# YC3122 register map
Series: ARMCM0; File version: 1.0
CPU: CM0 r1p0, little endian, no MPU, no FPU, 8 interrupt priority bits
Registers are 32-bit, read-write, reset 0x0 unless marked. A register's access mark holds for its fields unless they carry their own. Offsets are from the block's base; [hi:lo] are bit positions.

## MRSTGEN
Base 0x000F8574
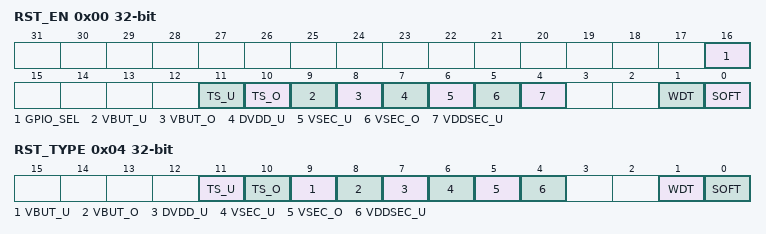
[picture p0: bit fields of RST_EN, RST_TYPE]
0x00 RST_EN
  [16] GPIO_SEL — 复位GPIO选择 0: ice_rst/m0_dbg_rst复位外设时,不 复位GPIO. 1: ice_rst/m0_dbg_rst复位外设时,复 位GPIO
  [11] TS_U — 1: 使能低温自检复位功能
  [10] TS_O — 1: 使能高温自检复位功能
  [9] VBUT_U — 1: 使能纽扣电池3.3v输出低压自检复位功能
  [8] VBUT_O — 1: 使能纽扣电池3.3v输出高压自检复位功能
  [7] DVDD_U — 1: 使能纽扣电池1.2v输出低压自检复位功能
  [6] VSEC_U — 1: 使能锂电池3.3v输出低压自检复位功能
  [5] VSEC_O — 1: 使能锂电池3.3v输出高压自检复位功能
  [4] VDDSEC_U — 1: 使能安全域电源1.2v输出低压自检复位功能
  [1] WDT — 1: 使能看门狗复位功能
  [0] SOFT — 1: 使能软件复位功能
0x04 RST_TYPE
  [11] TS_U — 软件可读写,若对应的复位信号触发,则硬件自动置1 ,清0需由软件完成。
  [10] TS_O — 软件可读写,若对应的复位信号触发,则硬件自动置1 ,清0需由软件完成。
  [9] VBUT_U — 软件可读写,若对应的复位信号触发,则硬件自动置1 ,清0需由软件完成。
  [8] VBUT_O — 软件可读写,若对应的复位信号触发,则硬件自动置1 ,清0需由软件完成。
  [7] DVDD_U — 软件可读写,若对应的复位信号触发,则硬件自动置1 ,清0需由软件完成。
  [6] VSEC_U — 软件可读写,若对应的复位信号触发,则硬件自动置1 ,清0需由软件完成。
  [5] VSEC_O — 软件可读写,若对应的复位信号触发,则硬件自动置1 ,清0需由软件完成。
  [4] VDDSEC_U — 软件可读写,若对应的复位信号触发,则硬件自动置1 ,清0需由软件完成。
  [1] WDT — 软件可读写,若对应的复位信号触发,则硬件自动置1 ,清0需由软件完成。
  [0] SOFT — 软件可读写,若对应的复位信号触发,则硬件自动置1 ,清0需由软件完成。
0x08 RESET
  [7:0] RESET wo — 复位使能: 写入 "0x55" ,触发软件复位,sw_rst 写入 "0x50" ,触发软件复位,ic_rst 写入 "0xAB“ ,触发sci复位,rst_sci 写入 "0xAE“ ,触发sci2复位,rst_sci_ 2 写入 "0xC3" ,触发7811复位,rst_7811

## MSECURE
Base 0x000F85C0
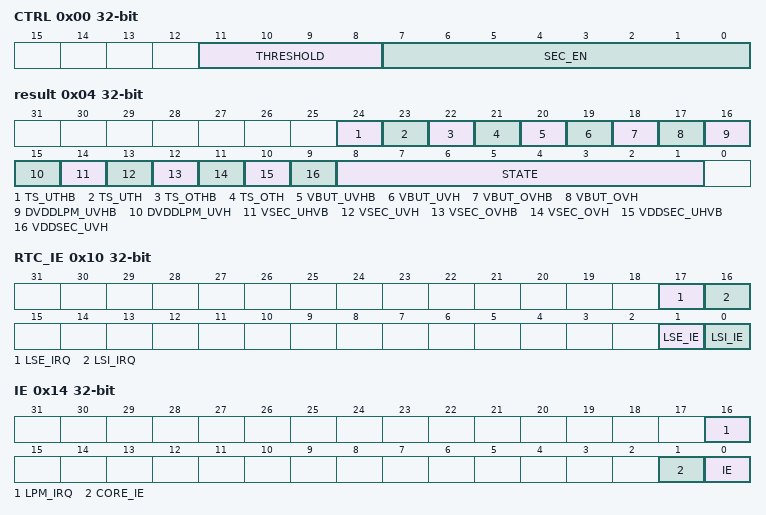
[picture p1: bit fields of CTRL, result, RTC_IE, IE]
0x00 CTRL
  [11:8] THRESHOLD — sensor检测警报持续时间门限,大于此门限发出 警报,否则不报警。 时间门限值: (2^sensor_delay)*hclk
  [7:0] SEC_EN — 1: sensor检测使能。 [7]: 低温自检,ad_ts_uth/uthb [6]: 高温自检,ad_ts_oth/othb [5]: 纽扣电池3.3v输出低压自检,ad_vbat_ uvh/uvhb [4]: 纽扣电池3.3v输出高压自检,ad_vbat_ ovh/ovhb [3]: 纽扣电池1.2v输出低压自检,ad_dvddl pm_uvh/uvhb [2]: 锂电池3.3v输出低压自检,ad_vsec_u v/uvb [1]: 锂电池3.3v输出高压自检,ad_vsec_o v/ovb [0]: 安全域电源1.2v输出低压自检,ad_vdds ec_uv/uvb
0x04 result
  [24] TS_UTHB ro — 低温自检电路结果输出
  [23] TS_UTH ro — 低温自检电路结果输出
  [22] TS_OTHB ro — 高温自检电路结果输出
  [21] TS_OTH ro — 高温自检电路结果输出
  [20] VBUT_UVHB ro — 纽扣电池3.3v输出低压自检电路结果输出
  [19] VBUT_UVH ro — 纽扣电池3.3v输出低压自检电路结果输出
  [18] VBUT_OVHB ro — 纽扣电池3.3v输出高压自检电路结果输出
  [17] VBUT_OVH ro — 纽扣电池3.3v输出高压自检电路结果输出
  [16] DVDDLPM_UVHB ro — 纽扣电池1.2v输出低压自检电路结果输出
  [15] DVDDLPM_UVH ro — 纽扣电池1.2v输出低压自检电路结果输出
  [14] VSEC_UHVB ro — 锂电池3.3v输出低压自检电路结果输出
  [13] VSEC_UVH ro — 锂电池3.3v输出低压自检电路结果输出
  [12] VSEC_OVHB ro — 锂电池3.3v输出高压自检电路结果输出
  [11] VSEC_OVH ro — 锂电池3.3v输出高压自检电路结果输出
  [10] VDDSEC_UHVB ro — 安全域电源1.2v输出低压自检电路结果输出
  [9] VDDSEC_UVH ro — 安全域电源1.2v输出低压自检电路结果输出
  [8:1] STATE ro — 1: 对应检测项报警。 [8]: 低温自检警报 [7]: 高温自检警报 [6]: 纽扣电池3.3v输出低压自检警报 [5]: 纽扣电池3.3v输出高压自检警报 [4]: 纽扣电池1.2v输出低压自检警报 [3]: 锂电池3.3v输出低压自检警报 [2]: 锂电池3.3v输出高压自检警报 [1]: 安全域电源1.2v输出低压自检警报
0x10 RTC_IE
  [17] LSE_IRQ ro — rtc_lse_irq flag, 仅指中断标志 ,清除需要使用RTC_LSE寄存器
  [16] LSI_IRQ ro — rtc_lsi_irq flag, 仅指中断标志 ,清除需要使用RTC_LSI寄存器
  [1] LSE_IE — 1: enable rtc_lse irq
  [0] LSI_IE — 1: enable rtc_lsi irq
0x14 IE
  [16] LPM_IRQ ro — lpm security irq status
  [1] CORE_IE — CORE SEC中断开关 1: enable core security even t interrupt
  [0] IE — SEC中断总开关 both lpm security events and core security events will t rigger secure_irq
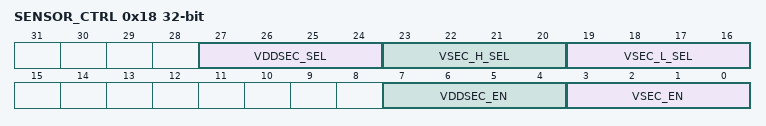
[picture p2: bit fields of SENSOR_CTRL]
0x18 SENSOR_CTRL
  [27:24] VDDSEC_SEL — threshold voltage select ion(sim tt 50deg, voltage fr om low to high): 0000: 867mV. 0001: 887mV. 0010: 907mV. 0011: 927mV. 0100: 947mV. 0101: 967mV. 0110: 987mV. 0111: 1005mV. 1000: 1025mV. 1001: 1045mV. 1010: 1065mV. 1011: 1085mV. 1100: 1105mV. 1101: 1125mV. 1110: 1145mV. 1111: 1165mV
  [23:20] VSEC_H_SEL — threshold voltage select ion(sim tt 50deg, voltage fr om low to high): 0000: 3.369. 0001: 3.419. 0010: 3.469. 0011: 3.522. 0100: 3.576. 0101: 3.631. 0110: 3.688. 0111: 3.748. 1000: 3.809. 1001: 3.872. 1010: 3.937. 1011: 4.005. 1100: 4.074. 1101: 4.147. 1110: 4.222. 1111: 4.299
  [19:16] VSEC_L_SEL — threshold voltage select ion(sim tt 50deg, voltage fr om low to high): 0000: 1.938. 0001: 1.971. 0010: 2.005. 0011: 2.040. 0100: 2.076. 0101: 2.113. 0110: 2.152. 0111: 2.193. 1000: 2.235. 1001: 2.278. 1010: 2.324. 1011: 2.371. 1100: 2.420. 1101: 2.471. 1110: 2.525. 1111: 2.580
  [7:4] VDDSEC_EN — 0x5, disable sensor, els e enable sensor
  [3:0] VSEC_EN — 0x5, disable sensor, els e enable sensor
